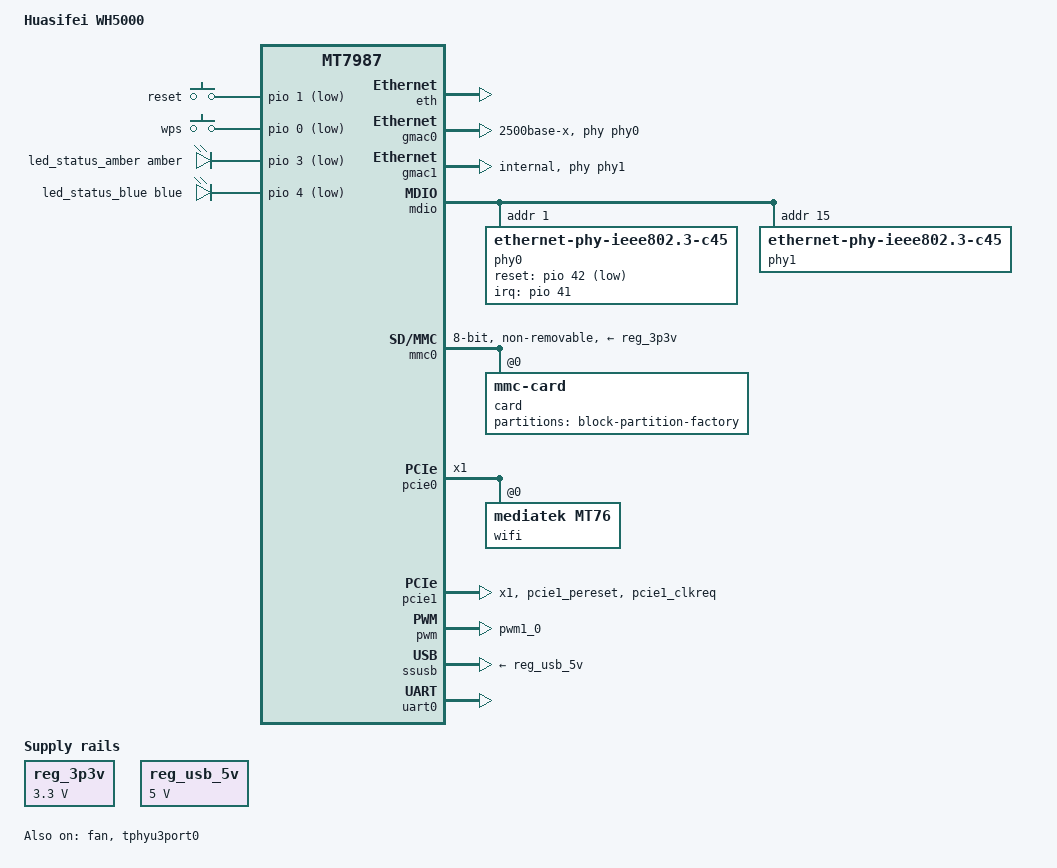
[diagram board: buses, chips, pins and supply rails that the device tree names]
// SPDX-License-Identifier: (GPL-2.0 OR MIT)

/dts-v1/;
#include "mt7987a.dtsi"
#include <dt-bindings/input/input.h>

/ {
	model = "Huasifei WH5000";
	compatible = "huasifei,wh5000", "mediatek,mt7987a", "mediatek,mt7987";

	aliases {
		led-boot = &led_status_blue;
		led-failsafe = &led_status_amber;
		led-upgrade = &led_status_amber;
		serial0 = &uart0;
	};

	chosen {
		bootargs = "earlycon=uart8250,mmio32,0x11000000 \
			    root=PARTLABEL=rootfs rootwait pci=pcie_bus_perf";
		stdout-path = "serial0:115200n8";
	};

	gpio-keys {
		compatible = "gpio-keys";

		button-reset {
			label = "reset";
			linux,code = <KEY_RESTART>;
			gpios = <&pio 1 GPIO_ACTIVE_LOW>;
			debounce-interval = <10>;
		};

		button-wps {
			label = "wps";
			linux,code = <KEY_WPS_BUTTON>;
			gpios = <&pio 0 GPIO_ACTIVE_LOW>;
			debounce-interval = <10>;
		};
	};

	leds {
		compatible = "gpio-leds";

		led_status_amber: led-3 {
			function = LED_FUNCTION_WLAN_2GHZ;
			color = <LED_COLOR_ID_AMBER>;
			gpios = <&pio 3 GPIO_ACTIVE_LOW>;
		};

		led_status_blue: led-4 {
			function = LED_FUNCTION_WLAN_5GHZ;
			color = <LED_COLOR_ID_BLUE>;
			gpios = <&pio 4 GPIO_ACTIVE_LOW>;
		};
	};

	reg_3p3v: regulator-3p3v {
		compatible = "regulator-fixed";
		regulator-name = "fixed-3.3V";
		regulator-min-microvolt = <3300000>;
		regulator-max-microvolt = <3300000>;
		regulator-boot-on;
		regulator-always-on;
	};

	reg_usb_5v: regulator-usb-5v {
		compatible = "regulator-fixed";
		regulator-name = "usb-5v";
		regulator-max-microvolt = <5000000>;
		regulator-min-microvolt = <5000000>;
		regulator-boot-on;
		regulator-always-on;
	};
};

&eth {
	status = "okay";
};

&fan {
	pwms = <&pwm 1 50000 0>;
	cooling-levels = <0 10 20 30 40 50 60 70 80 90 100 110 120 130 140 150 160 170 180 190 200 210 220 240 255>;
	interrupts-extended = <&pio 6 IRQ_TYPE_EDGE_FALLING>;
	pulses-per-revolution = <2>;
	status = "okay";
};

&gmac0 {
	phy-mode = "2500base-x";
	phy-handle = <&phy0>;
	status = "okay";
};

&gmac1 {
	phy-mode = "internal";
	phy-handle = <&phy1>;
	status = "okay";
};

&mdio {
	/* RTL8221B-VB-CG 2.5Gbps PHY (away from power) eth0 */
	phy0: phy@1 {
		compatible = "ethernet-phy-ieee802.3-c45";
		reg = <1>;
		reset-gpios = <&pio 42 GPIO_ACTIVE_LOW>;
		reset-assert-us = <100000>;
		reset-deassert-us = <100000>;
		interrupt-parent = <&pio>;
		interrupts = <41 IRQ_TYPE_LEVEL_LOW>;
		realtek,aldps-enable;
	};

	/* built-in 2.5G Ethernet PHY (near power) eth1 */
	phy1: phy@15 {
		compatible = "ethernet-phy-ieee802.3-c45";
		reg = <15>;
		pinctrl-names = "i2p5gbe-led";
		pinctrl-0 = <&i2p5gbe_led0_pins>;

		leds {
			#address-cells = <1>;
			#size-cells = <0>;

			led@0 {
				reg = <0>;
				function = LED_FUNCTION_WAN;
				color = <LED_COLOR_ID_RED>;
			};
		};
	};
};

&mmc0 {
	pinctrl-names = "default", "state_uhs";
	pinctrl-0 = <&mmc_pins_default>;
	pinctrl-1 = <&mmc_pins_uhs>;
	bus-width = <8>;
	max-frequency = <48000000>;
	cap-mmc-highspeed;
	vmmc-supply = <&reg_3p3v>;
	non-removable;
	status = "okay";

	card@0 {
		compatible = "mmc-card";
		reg = <0>;

		block {
			compatible = "block-device";

			partitions {
				block-partition-factory {
					partname = "factory";

					nvmem-layout {
						compatible = "fixed-layout";
						#address-cells = <1>;
						#size-cells = <1>;

						eeprom_factory_0: eeprom@0 {
							reg = <0x0 0x1e00>;
						};
					};
				};
			};
		};
	};
};

&pcie0 {
	pinctrl-names = "default";
	pinctrl-0 = <&pcie0_pins>;
	wifi-reset-gpios = <&pio 38 GPIO_ACTIVE_LOW>;
	wifi-reset-msleep = <1000>;
	num-lanes = <1>;
	status = "okay";

	pcie@0,0 {
		reg = <0x0000 0 0 0 0>;
		#address-cells = <3>;
		#size-cells = <2>;
		device_type = "pci";

		wifi@0,0 {
			compatible = "mediatek,mt76";
			reg = <0x0000 0 0 0 0>;

			nvmem-cells = <&eeprom_factory_0>;
			nvmem-cell-names = "eeprom";

			#address-cells = <1>;
			#size-cells = <0>;

			ieee80211-freq-limit = <2400000 2500000>,
					       <5170000 5835000>;
		};
	};
};

&pcie1 {
	pinctrl-names = "default";
	pinctrl-0 = <&pcie1_pins>;
	num-lanes = <1>;
	status = "okay";
};

&pio {
	/* override mt7987.dtsi pcie1_pins: remove pcie1_wake
	 * because GPIO 38 (PCIE_WAKE_N_1) is used by pcie0 as wifi-reset-gpios
	 */
	pcie1_pins: pcie1-pins {
		mux {
			function = "pcie";
			groups = "pcie1_pereset", "pcie1_clkreq";
		};
	};

	pwm_fan_pins: pwm-fan-pins {
		mux {
			function = "pwm";
			groups = "pwm1_0";
		};
	};
};

&pwm {
	status = "okay";
	pinctrl-names = "default";
	pinctrl-0 = <&pwm_fan_pins>;
};

&ssusb {
	status = "okay";
	vusb33-supply = <&reg_3p3v>;
	vbus-supply = <&reg_usb_5v>;
};

&tphyu3port0 {
	status = "okay";
};

&uart0 {
	pinctrl-names = "default";
	pinctrl-0 = <&uart0_pins>;
	status = "okay";
};
